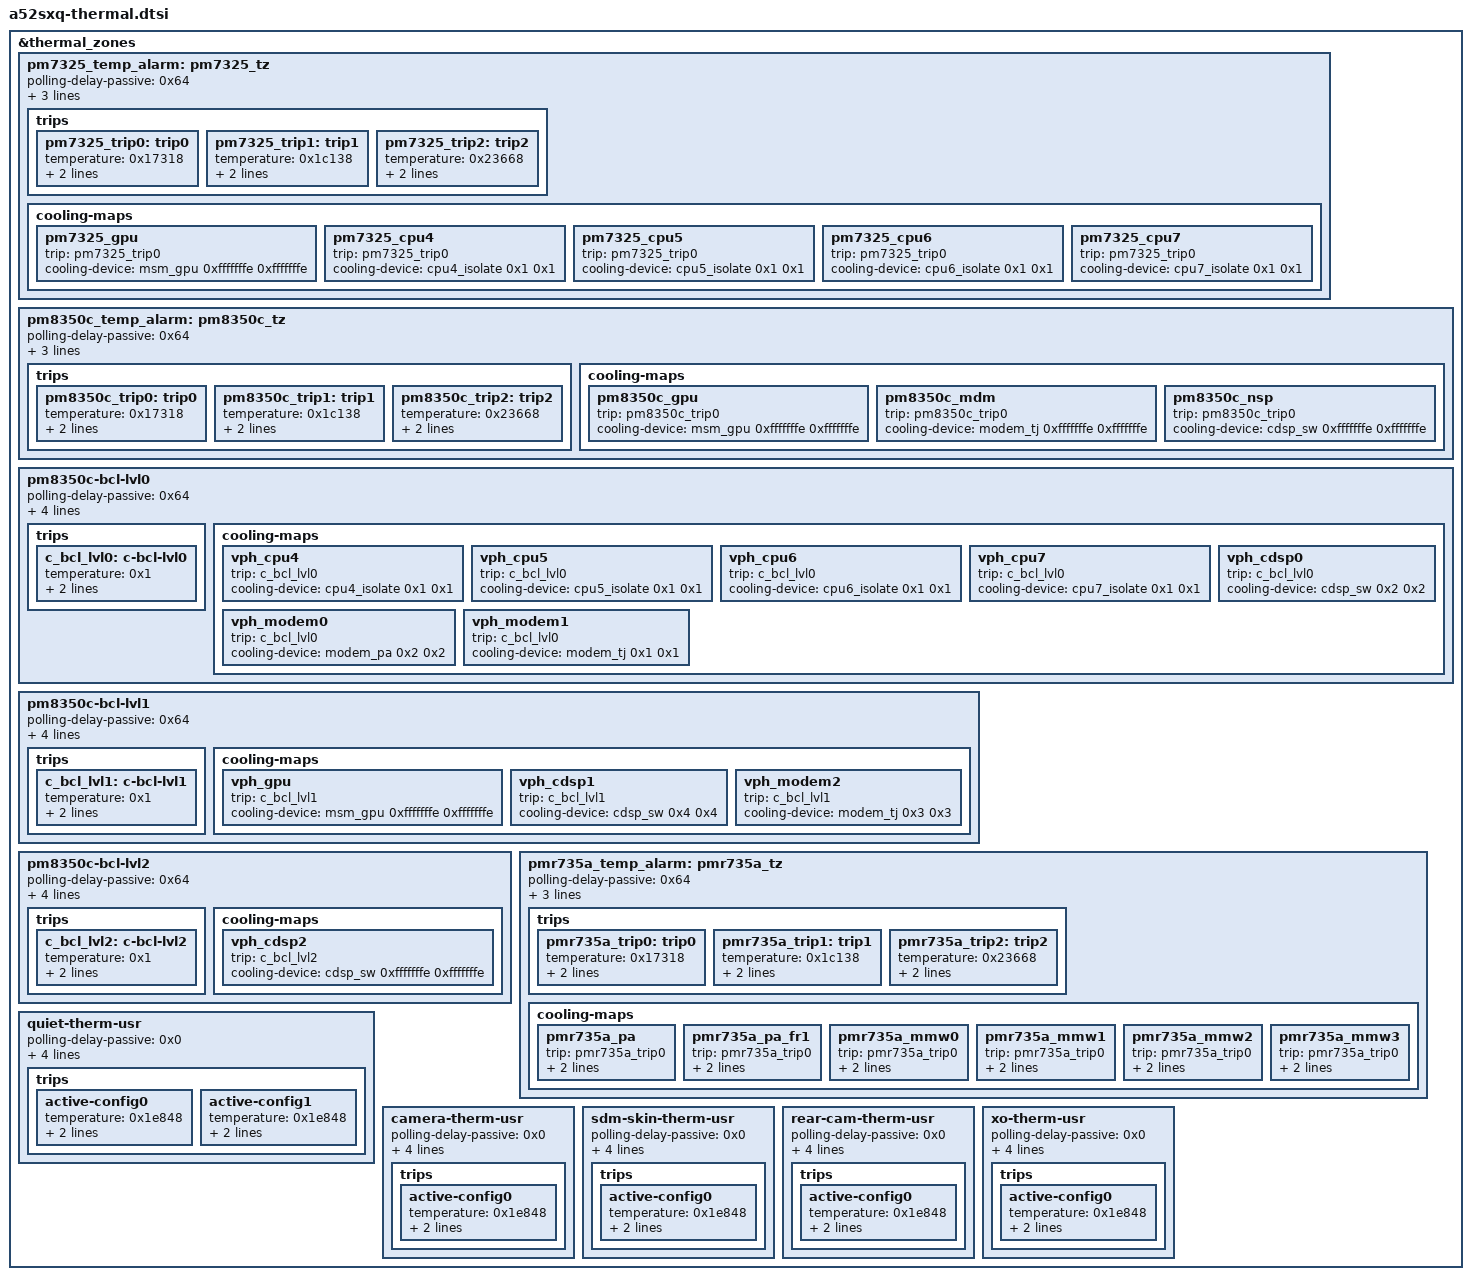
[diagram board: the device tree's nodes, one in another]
// SPDX-License-Identifier: GPL-2.0
/*
 * a52sxq board description for the Qualcomm 6.12 yupik base: thermal
 * GENERATED by tools/gen.py from the phone's stock dtbo (5.4 bindings, values verbatim).
 * Do not edit: hand-written 6.12 changes live in a52sxq-bsp612-fixups.dtsi.
 */

&thermal_zones {

	pm7325_temp_alarm: pm7325_tz {
		polling-delay-passive = <0x64>;
		polling-delay = <0x0>;
		thermal-governor = "step_wise";
		thermal-sensors = <&pm7325_tz>;

		trips {

			pm7325_trip0: trip0 {
				temperature = <0x17318>;
				hysteresis = <0x0>;
				type = "passive";
			};

			pm7325_trip1: trip1 {
				temperature = <0x1c138>;
				hysteresis = <0x0>;
				type = "critical";
			};

			pm7325_trip2: trip2 {
				temperature = <0x23668>;
				hysteresis = <0x0>;
				type = "critical";
			};
		};

		cooling-maps {

			pm7325_gpu {
				trip = <&pm7325_trip0>;
				cooling-device = <&msm_gpu 0xfffffffe 0xfffffffe>;
			};

			pm7325_cpu4 {
				trip = <&pm7325_trip0>;
				cooling-device = <&cpu4_isolate 0x1 0x1>;
			};

			pm7325_cpu5 {
				trip = <&pm7325_trip0>;
				cooling-device = <&cpu5_isolate 0x1 0x1>;
			};

			pm7325_cpu6 {
				trip = <&pm7325_trip0>;
				cooling-device = <&cpu6_isolate 0x1 0x1>;
			};

			pm7325_cpu7 {
				trip = <&pm7325_trip0>;
				cooling-device = <&cpu7_isolate 0x1 0x1>;
			};
		};
	};

	pm8350c_temp_alarm: pm8350c_tz {
		polling-delay-passive = <0x64>;
		polling-delay = <0x0>;
		thermal-governor = "step_wise";
		thermal-sensors = <&pm8350c_tz>;

		trips {

			pm8350c_trip0: trip0 {
				temperature = <0x17318>;
				hysteresis = <0x0>;
				type = "passive";
			};

			pm8350c_trip1: trip1 {
				temperature = <0x1c138>;
				hysteresis = <0x0>;
				type = "critical";
			};

			pm8350c_trip2: trip2 {
				temperature = <0x23668>;
				hysteresis = <0x0>;
				type = "critical";
			};
		};

		cooling-maps {

			pm8350c_gpu {
				trip = <&pm8350c_trip0>;
				cooling-device = <&msm_gpu 0xfffffffe 0xfffffffe>;
			};

			pm8350c_mdm {
				trip = <&pm8350c_trip0>;
				cooling-device = <&modem_tj 0xfffffffe 0xfffffffe>;
			};

			pm8350c_nsp {
				trip = <&pm8350c_trip0>;
				cooling-device = <&cdsp_sw 0xfffffffe 0xfffffffe>;
			};
		};
	};

	pm8350c-bcl-lvl0 {
		polling-delay-passive = <0x64>;
		polling-delay = <0x0>;
		thermal-governor = "step_wise";
		thermal-sensors = <&pm8350c_bcl 0x5>;
		disable-thermal-zone;

		trips {

			c_bcl_lvl0: c-bcl-lvl0 {
				temperature = <0x1>;
				hysteresis = <0x1>;
				type = "passive";
			};
		};

		cooling-maps {

			vph_cpu4 {
				trip = <&c_bcl_lvl0>;
				cooling-device = <&cpu4_isolate 0x1 0x1>;
			};

			vph_cpu5 {
				trip = <&c_bcl_lvl0>;
				cooling-device = <&cpu5_isolate 0x1 0x1>;
			};

			vph_cpu6 {
				trip = <&c_bcl_lvl0>;
				cooling-device = <&cpu6_isolate 0x1 0x1>;
			};

			vph_cpu7 {
				trip = <&c_bcl_lvl0>;
				cooling-device = <&cpu7_isolate 0x1 0x1>;
			};

			vph_cdsp0 {
				trip = <&c_bcl_lvl0>;
				cooling-device = <&cdsp_sw 0x2 0x2>;
			};

			vph_modem0 {
				trip = <&c_bcl_lvl0>;
				cooling-device = <&modem_pa 0x2 0x2>;
			};

			vph_modem1 {
				trip = <&c_bcl_lvl0>;
				cooling-device = <&modem_tj 0x1 0x1>;
			};
		};
	};

	pm8350c-bcl-lvl1 {
		polling-delay-passive = <0x64>;
		polling-delay = <0x0>;
		thermal-governor = "step_wise";
		thermal-sensors = <&pm8350c_bcl 0x6>;
		disable-thermal-zone;

		trips {

			c_bcl_lvl1: c-bcl-lvl1 {
				temperature = <0x1>;
				hysteresis = <0x1>;
				type = "passive";
			};
		};

		cooling-maps {

			vph_gpu {
				trip = <&c_bcl_lvl1>;
				cooling-device = <&msm_gpu 0xfffffffe 0xfffffffe>;
			};

			vph_cdsp1 {
				trip = <&c_bcl_lvl1>;
				cooling-device = <&cdsp_sw 0x4 0x4>;
			};

			vph_modem2 {
				trip = <&c_bcl_lvl1>;
				cooling-device = <&modem_tj 0x3 0x3>;
			};
		};
	};

	pm8350c-bcl-lvl2 {
		polling-delay-passive = <0x64>;
		polling-delay = <0x0>;
		thermal-governor = "step_wise";
		thermal-sensors = <&pm8350c_bcl 0x7>;
		disable-thermal-zone;

		trips {

			c_bcl_lvl2: c-bcl-lvl2 {
				temperature = <0x1>;
				hysteresis = <0x1>;
				type = "passive";
			};
		};

		cooling-maps {

			vph_cdsp2 {
				trip = <&c_bcl_lvl2>;
				cooling-device = <&cdsp_sw 0xfffffffe 0xfffffffe>;
			};
		};
	};

	pmr735a_temp_alarm: pmr735a_tz {
		polling-delay-passive = <0x64>;
		polling-delay = <0x0>;
		thermal-governor = "step_wise";
		thermal-sensors = <&pmr735a_tz>;

		trips {

			pmr735a_trip0: trip0 {
				temperature = <0x17318>;
				hysteresis = <0x0>;
				type = "passive";
			};

			pmr735a_trip1: trip1 {
				temperature = <0x1c138>;
				hysteresis = <0x0>;
				type = "critical";
			};

			pmr735a_trip2: trip2 {
				temperature = <0x23668>;
				hysteresis = <0x0>;
				type = "critical";
			};
		};

		cooling-maps {

			pmr735a_pa {
				trip = <&pmr735a_trip0>;
				cooling-device = <&modem_pa_dsc 0xfffffffe 0xfffffffe>;
			};

			pmr735a_pa_fr1 {
				trip = <&pmr735a_trip0>;
				cooling-device = <&modem_pa_fr1_dsc 0xfffffffe 0xfffffffe>;
			};

			pmr735a_mmw0 {
				trip = <&pmr735a_trip0>;
				cooling-device = <&modem_mmw0 0xfffffffe 0xfffffffe>;
			};

			pmr735a_mmw1 {
				trip = <&pmr735a_trip0>;
				cooling-device = <&modem_mmw1 0xfffffffe 0xfffffffe>;
			};

			pmr735a_mmw2 {
				trip = <&pmr735a_trip0>;
				cooling-device = <&modem_mmw2 0xfffffffe 0xfffffffe>;
			};

			pmr735a_mmw3 {
				trip = <&pmr735a_trip0>;
				cooling-device = <&modem_mmw3 0xfffffffe 0xfffffffe>;
			};
		};
	};

	quiet-therm-usr {
		polling-delay-passive = <0x0>;
		polling-delay = <0x0>;
		thermal-governor = "user_space";
		thermal-sensors = <&pmk8350_adc_tm 0x144>;
		wake-capable-sensor;

		trips {

			active-config0 {
				temperature = <0x1e848>;
				hysteresis = <0x3e8>;
				type = "passive";
			};

			active-config1 {
				temperature = <0x1e848>;
				hysteresis = <0x3e8>;
				type = "passive";
			};
		};
	};

	camera-therm-usr {
		polling-delay-passive = <0x0>;
		polling-delay = <0x0>;
		thermal-governor = "user_space";
		thermal-sensors = <&pmk8350_adc_tm 0x145>;
		wake-capable-sensor;

		trips {

			active-config0 {
				temperature = <0x1e848>;
				hysteresis = <0x3e8>;
				type = "passive";
			};
		};
	};

	sdm-skin-therm-usr {
		polling-delay-passive = <0x0>;
		polling-delay = <0x0>;
		thermal-governor = "user_space";
		thermal-sensors = <&pmk8350_adc_tm 0x146>;
		wake-capable-sensor;

		trips {

			active-config0 {
				temperature = <0x1e848>;
				hysteresis = <0x3e8>;
				type = "passive";
			};
		};
	};

	rear-cam-therm-usr {
		polling-delay-passive = <0x0>;
		polling-delay = <0x0>;
		thermal-governor = "user_space";
		thermal-sensors = <&pmk8350_adc_tm 0x147>;
		wake-capable-sensor;

		trips {

			active-config0 {
				temperature = <0x1e848>;
				hysteresis = <0x3e8>;
				type = "passive";
			};
		};
	};

	xo-therm-usr {
		polling-delay-passive = <0x0>;
		polling-delay = <0x0>;
		thermal-governor = "user_space";
		thermal-sensors = <&pmk8350_adc_tm 0x44>;
		wake-capable-sensor;

		trips {

			active-config0 {
				temperature = <0x1e848>;
				hysteresis = <0x3e8>;
				type = "passive";
			};
		};
	};
};

